# jbr_MDR1901VC1T register map
Registers are 32-bit, access not given, no defined reset value unless marked. A register's access mark holds for its fields unless they carry their own. Addresses are absolute; registers are grouped by the start of their names; [hi:lo] are bit positions; {n}, {i} and the like mark numbered series.

## TIMER3
0x40080000 TIMER3_CNT
  [15:0] CNT
0x40080004 TIMER3_PSG
  [15:0] PSG
0x40080008 TIMER3_ARR
  [15:0] ARR
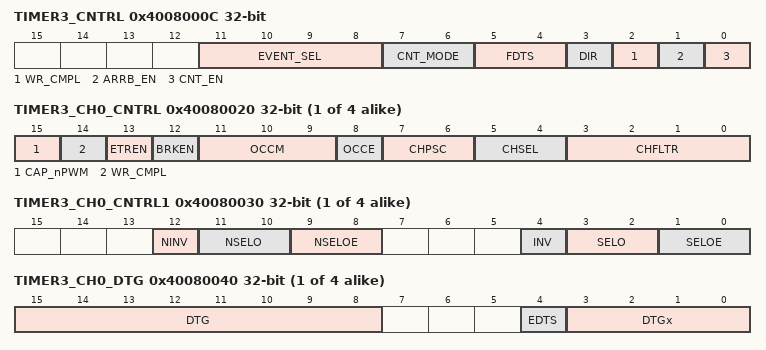
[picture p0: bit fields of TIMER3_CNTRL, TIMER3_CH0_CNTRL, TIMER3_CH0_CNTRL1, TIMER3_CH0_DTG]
0x4008000C TIMER3_CNTRL
  [11:8] EVENT_SEL, [7:6] CNT_MODE, [5:4] FDTS, [3] DIR, [2] WR_CMPL, [1] ARRB_EN, [0] CNT_EN
0x40080010 TIMER3_CCR0
  [15:0] CCR
0x40080014 TIMER3_CCR1
  [15:0] CCR
0x40080018 TIMER3_CCR2
  [15:0] CCR
0x4008001C TIMER3_CCR3
  [15:0] CCR
{0x40080020+4i} TIMER3_CH{i}_CNTRL (i=0..3)
  [15] CAP_nPWM, [14] WR_CMPL, [13] ETREN, [12] BRKEN, [11:9] OCCM, [8] OCCE, [7:6] CHPSC, [5:4] CHSEL, [3:0] CHFLTR
{0x40080030+4i} TIMER3_CH{i}_CNTRL1 (i=0..3)
  [12] NINV, [11:10] NSELO, [9:8] NSELOE, [4] INV, [3:2] SELO, [1:0] SELOE
{0x40080040+4i} TIMER3_CH{i}_DTG (i=0..3)
  [15:8] DTG, [4] EDTS, [3:0] DTGx
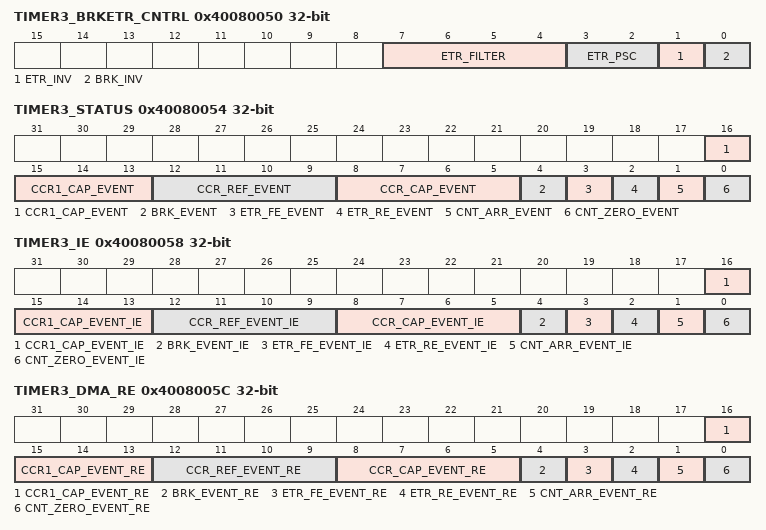
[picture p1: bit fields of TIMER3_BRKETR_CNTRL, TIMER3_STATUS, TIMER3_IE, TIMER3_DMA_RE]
0x40080050 TIMER3_BRKETR_CNTRL
  [7:4] ETR_FILTER, [3:2] ETR_PSC, [1] ETR_INV, [0] BRK_INV
0x40080054 TIMER3_STATUS
  [16:13] CCR1_CAP_EVENT, [12:9] CCR_REF_EVENT, [8:5] CCR_CAP_EVENT, [4] BRK_EVENT, [3] ETR_FE_EVENT, [2] ETR_RE_EVENT, [1] CNT_ARR_EVENT, [0] CNT_ZERO_EVENT
0x40080058 TIMER3_IE
  [16:13] CCR1_CAP_EVENT_IE, [12:9] CCR_REF_EVENT_IE, [8:5] CCR_CAP_EVENT_IE, [4] BRK_EVENT_IE, [3] ETR_FE_EVENT_IE, [2] ETR_RE_EVENT_IE, [1] CNT_ARR_EVENT_IE, [0] CNT_ZERO_EVENT_IE
0x4008005C TIMER3_DMA_RE
  [16:13] CCR1_CAP_EVENT_RE, [12:9] CCR_REF_EVENT_RE, [8:5] CCR_CAP_EVENT_RE, [4] BRK_EVENT_RE, [3] ETR_FE_EVENT_RE, [2] ETR_RE_EVENT_RE, [1] CNT_ARR_EVENT_RE, [0] CNT_ZERO_EVENT_RE
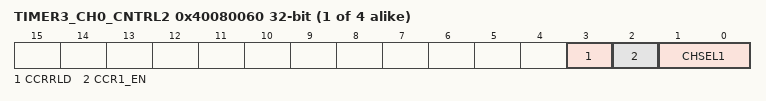
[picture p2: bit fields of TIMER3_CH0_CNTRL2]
{0x40080060+4i} TIMER3_CH{i}_CNTRL2 (i=0..3)
  [3] CCRRLD, [2] CCR1_EN, [1:0] CHSEL1
0x40080070 TIMER3_CCR01
  [15:0] CCR
0x40080074 TIMER3_CCR11
  [15:0] CCR
0x40080078 TIMER3_CCR21
  [15:0] CCR
0x4008007C TIMER3_CCR31
  [15:0] CCR

## PORTA
0x400A8000 PORTA_RXTX
  [15:0] RXTX
0x400A8004 PORTA_OE
  [15:0] OE
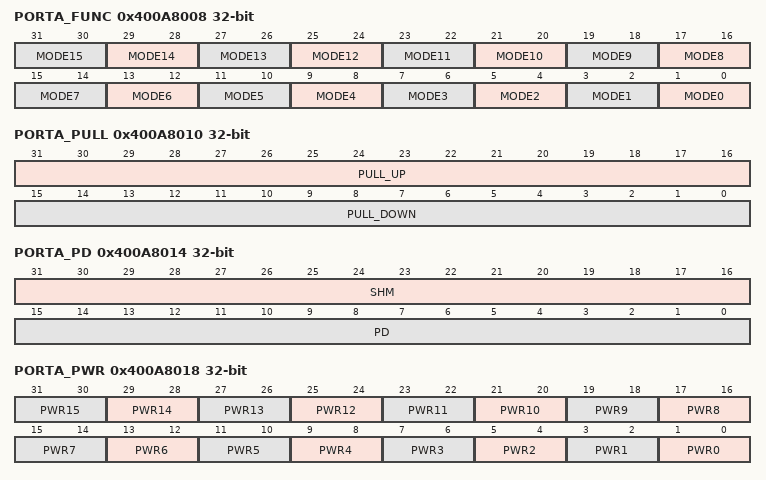
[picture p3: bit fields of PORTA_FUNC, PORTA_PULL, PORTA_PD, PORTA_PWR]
0x400A8008 PORTA_FUNC
  [2n+1:2n] MODE{n} (n=0..15)
0x400A800C PORTA_ANALOG
  [15:0] ANALOG_EN
0x400A8010 PORTA_PULL
  [31:16] PULL_UP, [15:0] PULL_DOWN
0x400A8014 PORTA_PD
  [31:16] SHM, [15:0] PD
0x400A8018 PORTA_PWR
  [2n+1:2n] PWR{n} (n=0..15)
0x400A801C PORTA_GFEN
  [15:0] GFEN

## PORTB
0x400B0000 PORTB_RXTX
  [15:0] RXTX
0x400B0004 PORTB_OE
  [15:0] OE
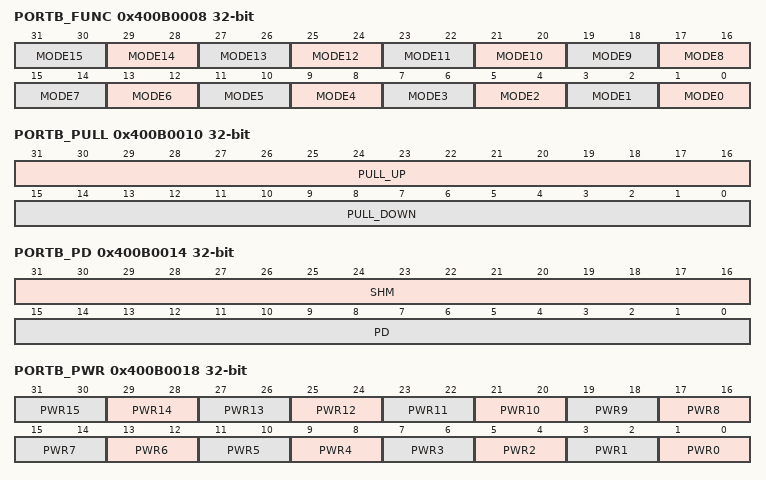
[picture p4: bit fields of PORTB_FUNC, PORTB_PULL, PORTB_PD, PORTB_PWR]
0x400B0008 PORTB_FUNC
  [2n+1:2n] MODE{n} (n=0..15)
0x400B000C PORTB_ANALOG
  [15:0] ANALOG_EN
0x400B0010 PORTB_PULL
  [31:16] PULL_UP, [15:0] PULL_DOWN
0x400B0014 PORTB_PD
  [31:16] SHM, [15:0] PD
0x400B0018 PORTB_PWR
  [2n+1:2n] PWR{n} (n=0..15)
0x400B001C PORTB_GFEN
  [15:0] GFEN

## PORTC
0x400B8000 PORTC_RXTX
  [15:0] RXTX
0x400B8004 PORTC_OE
  [15:0] OE
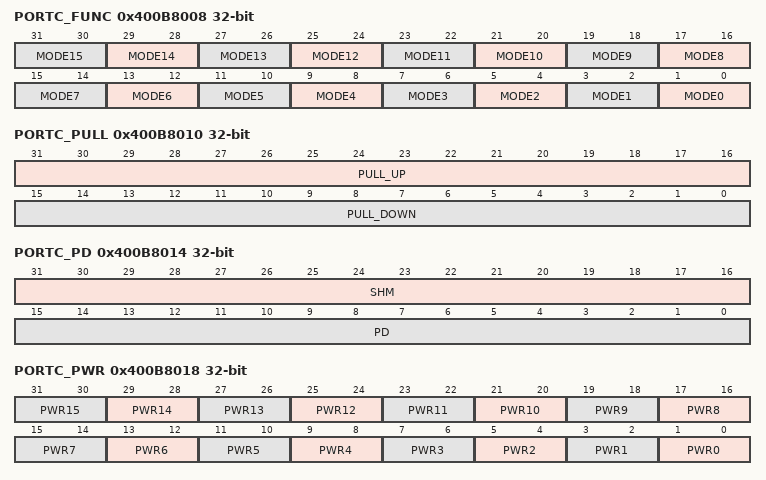
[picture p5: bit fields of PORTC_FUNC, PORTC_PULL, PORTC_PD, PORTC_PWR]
0x400B8008 PORTC_FUNC
  [2n+1:2n] MODE{n} (n=0..15)
0x400B800C PORTC_ANALOG
  [15:0] ANALOG_EN
0x400B8010 PORTC_PULL
  [31:16] PULL_UP, [15:0] PULL_DOWN
0x400B8014 PORTC_PD
  [31:16] SHM, [15:0] PD
0x400B8018 PORTC_PWR
  [2n+1:2n] PWR{n} (n=0..15)
0x400B801C PORTC_GFEN
  [15:0] GFEN

## PORTD
0x400C0000 PORTD_RXTX
  [15:0] RXTX
0x400C0004 PORTD_OE
  [15:0] OE
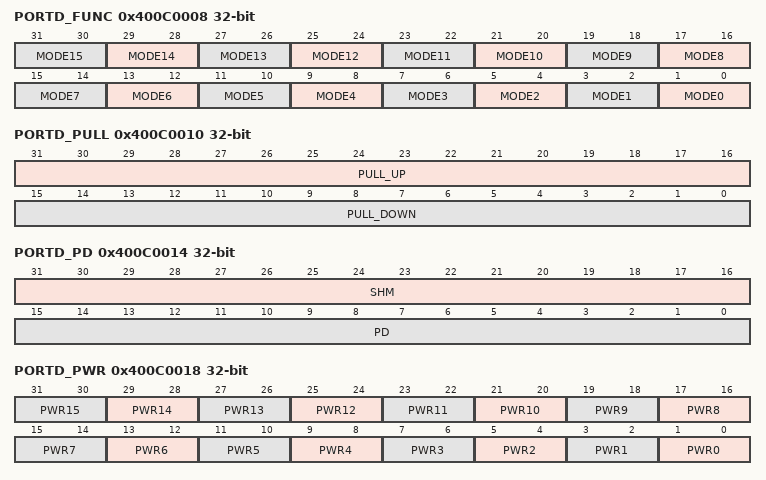
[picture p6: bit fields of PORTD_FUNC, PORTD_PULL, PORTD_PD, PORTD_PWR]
0x400C0008 PORTD_FUNC
  [2n+1:2n] MODE{n} (n=0..15)
0x400C000C PORTD_ANALOG
  [15:0] ANALOG_EN
0x400C0010 PORTD_PULL
  [31:16] PULL_UP, [15:0] PULL_DOWN
0x400C0014 PORTD_PD
  [31:16] SHM, [15:0] PD
0x400C0018 PORTD_PWR
  [2n+1:2n] PWR{n} (n=0..15)
0x400C001C PORTD_GFEN
  [15:0] GFEN

## PORTE
0x400C8000 PORTE_RXTX
  [15:0] RXTX
0x400C8004 PORTE_OE
  [15:0] OE
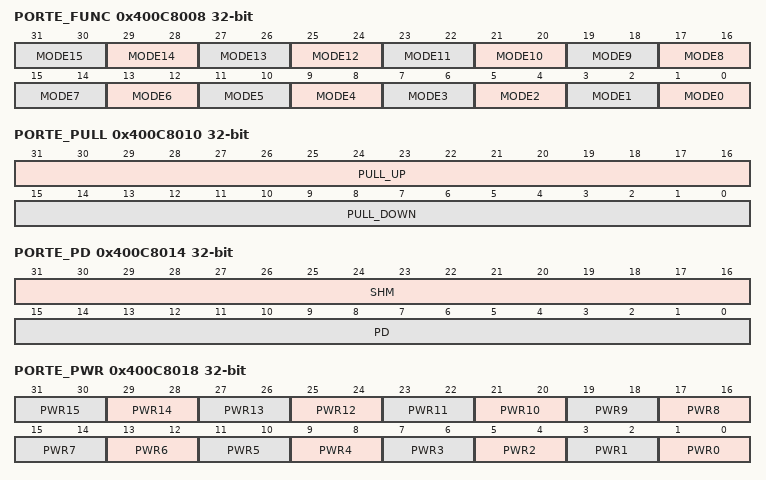
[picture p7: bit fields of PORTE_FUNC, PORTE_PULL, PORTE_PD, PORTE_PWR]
0x400C8008 PORTE_FUNC
  [2n+1:2n] MODE{n} (n=0..15)
0x400C800C PORTE_ANALOG
  [15:0] ANALOG_EN
0x400C8010 PORTE_PULL
  [31:16] PULL_UP, [15:0] PULL_DOWN
0x400C8014 PORTE_PD
  [31:16] SHM, [15:0] PD
0x400C8018 PORTE_PWR
  [2n+1:2n] PWR{n} (n=0..15)
0x400C801C PORTE_GFEN
  [15:0] GFEN

## PORTF
0x400E8000 PORTF_RXTX
  [15:0] RXTX
0x400E8004 PORTF_OE
  [15:0] OE
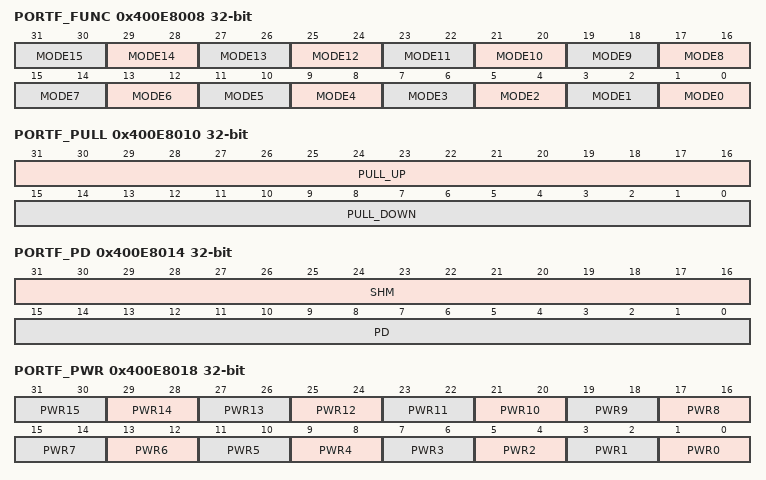
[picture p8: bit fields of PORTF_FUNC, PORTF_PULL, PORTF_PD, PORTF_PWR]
0x400E8008 PORTF_FUNC
  [2n+1:2n] MODE{n} (n=0..15)
0x400E800C PORTF_ANALOG
  [15:0] ANALOG_EN
0x400E8010 PORTF_PULL
  [31:16] PULL_UP, [15:0] PULL_DOWN
0x400E8014 PORTF_PD
  [31:16] SHM, [15:0] PD
0x400E8018 PORTF_PWR
  [2n+1:2n] PWR{n} (n=0..15)
0x400E801C PORTF_GFEN
  [15:0] GFEN
